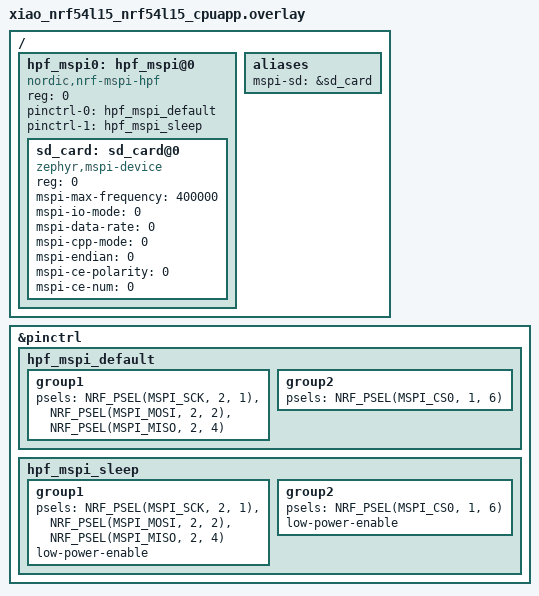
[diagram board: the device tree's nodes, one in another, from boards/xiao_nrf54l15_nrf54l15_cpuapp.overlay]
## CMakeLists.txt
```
# SPDX-License-Identifier: Apache-2.0
# MSPI Test Application for SD Card

cmake_minimum_required(VERSION 3.20.0)

find_package(Zephyr REQUIRED HINTS $ENV{ZEPHYR_BASE})
project(mspi_sd_test)

target_sources(app PRIVATE src/main.c)
```

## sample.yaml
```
sample:
  name: MSPI SD Card Test
  description: Test MSPI communication for SD card at 400kHz using HPF framework
tests:
  sample.mspi.sd_test:
    tags: mspi sd_card hpf
    platform_allow: xiao_nrf54l15_nrf54l15_cpuapp
    integration_platforms:
      - xiao_nrf54l15_nrf54l15_cpuapp
    harness: console
    harness_config:
      type: multi_line
      regex:
        - "MSPI device .* is ready"
        - "Command sent successfully"
```

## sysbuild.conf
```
# SPDX-License-Identifier: Apache-2.0
# Application core configuration for MSPI SD Card Test

# Enable HPF and MSPI
SB_CONFIG_HPF=y
SB_CONFIG_HPF_MSPI=y

# Disable default VPR launcher
SB_CONFIG_VPR_LAUNCHER=n

# Disable Partition Manager
SB_CONFIG_PARTITION_MANAGER=n

# MSPI will run on FLPR core
SB_CONFIG_HPF_MSPI_REMOTE_BOARD="xiao_nrf54l15/nrf54l15/cpuflpr"
```

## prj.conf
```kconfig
# SPDX-License-Identifier: Apache-2.0
# MSPI SD Card Test - Application Core Configuration

# IPC for communication with FLPR core
CONFIG_MBOX=y
CONFIG_IPC_SERVICE=y
CONFIG_IPC_SERVICE_BACKEND_ICMSG=y

# MSPI driver
CONFIG_MSPI=y

# GPIO for CS pin
CONFIG_GPIO=y

# Logging
CONFIG_LOG=y
CONFIG_LOG_DEFAULT_LEVEL=3

# Console
CONFIG_CONSOLE=y
CONFIG_UART_CONSOLE=y

# Increased stacks for SD card operations
CONFIG_MAIN_STACK_SIZE=8192
CONFIG_SYSTEM_WORKQUEUE_STACK_SIZE=4096
```

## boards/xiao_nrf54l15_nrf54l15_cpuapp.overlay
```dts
/*
 * SPDX-License-Identifier: Apache-2.0
 * 
 * MSPI device tree overlay for SD Card on XIAO Expansion Base
 * Pins: D8=SCK (P2.1), D9=MISO (P2.4), D10=MOSI (P2.2), D2=CS (P1.6)
 */

/ {
	/* Define MSPI controller using HPF */
	hpf_mspi0: hpf_mspi@0 {
		compatible = "nordic,nrf-mspi-hpf";
		reg = <0>;
		status = "okay";
		
		/* Pin configuration for SD card on expansion base */
		pinctrl-0 = <&hpf_mspi_default>;
		pinctrl-1 = <&hpf_mspi_sleep>;
		pinctrl-names = "default", "sleep";
		
		/* SD card device on MSPI bus */
		sd_card: sd_card@0 {
			compatible = "zephyr,mspi-device";
			reg = <0>;
			status = "okay";
			
			/* SD card SPI configuration */
			mspi-max-frequency = <400000>;  /* 400 kHz for initialization */
			mspi-io-mode = <0>;  /* MSPI_IO_MODE_SINGLE */
			mspi-data-rate = <0>;  /* MSPI_DATA_RATE_SINGLE */
			mspi-cpp-mode = <0>;  /* MSPI_CPP_MODE_0 (SPI Mode 0) */
			mspi-endian = <0>;  /* MSPI_XFER_LITTLE_ENDIAN */
			mspi-ce-polarity = <0>;  /* MSPI_CE_ACTIVE_LOW */
			mspi-ce-num = <0>;
		};
	};
};

&pinctrl {
	/* MSPI pins for SD card - using expansion base SPI pins */
	hpf_mspi_default: hpf_mspi_default {
		group1 {
			/* SCK, MOSI, MISO pins */
			psels = <NRF_PSEL(MSPI_SCK, 2, 1)>,   /* D8 - SCK */
					<NRF_PSEL(MSPI_MOSI, 2, 2)>,  /* D10 - MOSI */
					<NRF_PSEL(MSPI_MISO, 2, 4)>;  /* D9 - MISO */
		};
		group2 {
			/* CS pin */
			psels = <NRF_PSEL(MSPI_CS0, 1, 6)>;  /* D2 - CS */
		};
	};
	
	hpf_mspi_sleep: hpf_mspi_sleep {
		group1 {
			psels = <NRF_PSEL(MSPI_SCK, 2, 1)>,
					<NRF_PSEL(MSPI_MOSI, 2, 2)>,
					<NRF_PSEL(MSPI_MISO, 2, 4)>;
			low-power-enable;
		};
		group2 {
			psels = <NRF_PSEL(MSPI_CS0, 1, 6)>;
			low-power-enable;
		};
	};
};

/ {
	aliases {
		mspi-sd = &sd_card;
	};
};
```

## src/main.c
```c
/*
 * SPDX-License-Identifier: Apache-2.0
 * 
 * MSPI SD Card Test Application
 * Tests MSPI communication at 400kHz in single-line SPI mode
 */

#include <zephyr/kernel.h>
#include <zephyr/device.h>
#include <zephyr/drivers/mspi.h>
#include <zephyr/logging/log.h>

LOG_MODULE_REGISTER(mspi_sd_test, LOG_LEVEL_INF);

#define MSPI_NODE DT_NODELABEL(hpf_mspi0)

int main(void)
{
	const struct device *mspi_dev;
	int ret;

	LOG_INF("===========================================");
	LOG_INF("MSPI SD Card Test - Starting");
	LOG_INF("Testing MSPI at 400kHz in SPI mode");
	LOG_INF("===========================================");

	/* Get MSPI device */
	mspi_dev = DEVICE_DT_GET(MSPI_NODE);
	if (!device_is_ready(mspi_dev)) {
		LOG_ERR("MSPI device not ready!");
		return -1;
	}

	LOG_INF("MSPI device %s is ready", mspi_dev->name);

	/* Configure MSPI controller */
	struct mspi_dt_spec mspi_spec = MSPI_DT_SPEC_GET(MSPI_NODE);
	ret = mspi_config(&mspi_spec);
	if (ret < 0) {
		LOG_ERR("Failed to configure MSPI: %d", ret);
		return ret;
	}

	LOG_INF("MSPI configured successfully");

	/* Configure device settings for SD card */
	struct mspi_dev_id dev_id = {
		.dev_idx = 0,
	};

	struct mspi_dev_cfg dev_cfg = {
		.ce_num = 0,  /* CS on first CE line */
		.freq = 400000,  /* 400kHz for SD initialization */
		.io_mode = MSPI_IO_MODE_SINGLE,  /* Single-line SPI */
		.data_rate = MSPI_DATA_RATE_SINGLE,
		.cpp_mode = MSPI_CPP_MODE_0,  /* SPI Mode 0 */
		.endian = MSPI_XFER_LITTLE_ENDIAN,
		.ce_polarity = MSPI_CE_ACTIVE_LOW,
		.dqs_enable = false,
	};

	ret = mspi_dev_config(mspi_dev, &dev_id, MSPI_DEVICE_CONFIG_ALL, &dev_cfg);
	if (ret < 0) {
		LOG_ERR("Failed to configure MSPI device: %d", ret);
		return ret;
	}

	LOG_INF("MSPI device configured: 400kHz, Single-line, SPI Mode 0");

	/* Test data - send CMD0 (GO_IDLE_STATE) to SD card */
	uint8_t tx_data[] = {0x40, 0x00, 0x00, 0x00, 0x00, 0x95};  /* CMD0 with CRC */
	uint8_t rx_data[6] = {0};

	LOG_INF("Sending test command (CMD0) to SD card...");

	/* Prepare MSPI transfer */
	struct mspi_xfer xfer = {
		.async = false,
		.xfer_mode = MSPI_PIO,
		.tx_dummy = 0,
		.cmd_length = 0,  /* No separate command phase for SPI mode */
		.addr_length = 0,  /* No address phase */
		.num_packet = 1,
		.packets = (struct mspi_xfer_packet[]) {
			{
				.dir = MSPI_TX,
				.cmd = 0,
				.address = 0,
				.data_buf = tx_data,
				.num_bytes = sizeof(tx_data),
			},
		},
	};

	ret = mspi_transceive(mspi_dev, &dev_id, &xfer);
	if (ret < 0) {
		LOG_ERR("MSPI transceive failed: %d", ret);
		return ret;
	}

	LOG_INF("Command sent successfully!");
	LOG_HEXDUMP_INF(tx_data, sizeof(tx_data), "TX Data:");

	LOG_INF("===========================================");
	LOG_INF("MSPI Test Complete");
	LOG_INF("===========================================");

	/* Keep running to observe output */
	while (1) {
		k_sleep(K_SECONDS(5));
		LOG_INF("MSPI test running...");
	}

	return 0;
}
```
